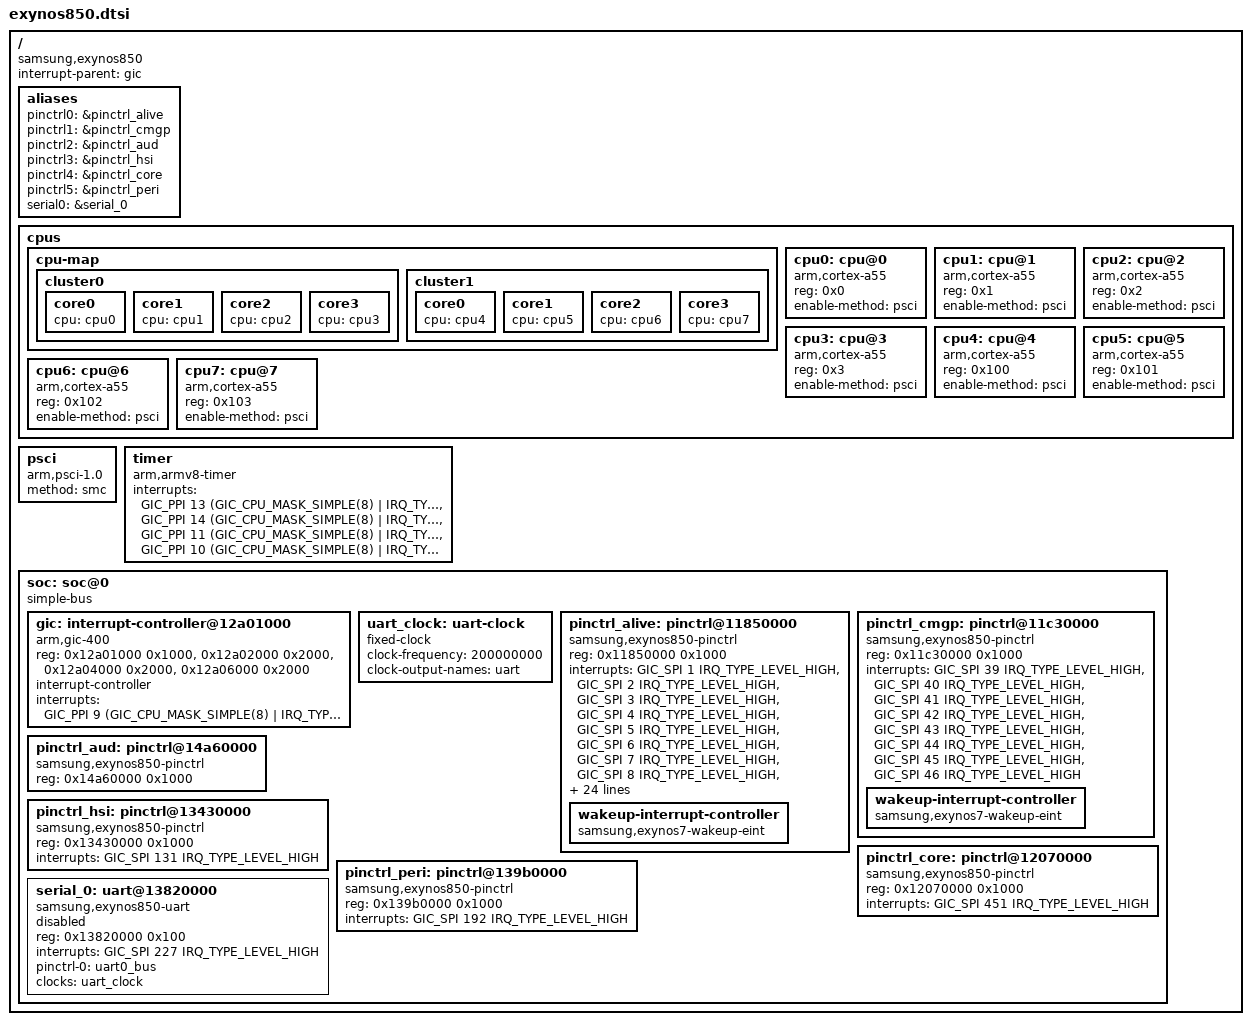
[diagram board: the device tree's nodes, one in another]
// SPDX-License-Identifier: GPL-2.0
/*
 * Samsung Exynos850 SoC device tree source
 *
 * Copyright (C) 2018 Samsung Electronics Co., Ltd.
 * Copyright (C) 2021 Linaro Ltd.
 *
 * Samsung Exynos850 SoC device nodes are listed in this file.
 * Exynos based board files can include this file and provide
 * values for board specific bindings.
 */

#include <dt-bindings/interrupt-controller/arm-gic.h>

/ {
	/* Also known under engineering name Exynos3830 */
	compatible = "samsung,exynos850";
	interrupt-parent = <&gic>;
	#address-cells = <2>;
	#size-cells = <1>;

	aliases {
		pinctrl0 = &pinctrl_alive;
		pinctrl1 = &pinctrl_cmgp;
		pinctrl2 = &pinctrl_aud;
		pinctrl3 = &pinctrl_hsi;
		pinctrl4 = &pinctrl_core;
		pinctrl5 = &pinctrl_peri;
		serial0 = &serial_0;
	};

	cpus {
		#address-cells = <1>;
		#size-cells = <0>;

		cpu-map {
			cluster0 {
				core0 {
					cpu = <&cpu0>;
				};
				core1 {
					cpu = <&cpu1>;
				};
				core2 {
					cpu = <&cpu2>;
				};
				core3 {
					cpu = <&cpu3>;
				};
			};

			cluster1 {
				core0 {
					cpu = <&cpu4>;
				};
				core1 {
					cpu = <&cpu5>;
				};
				core2 {
					cpu = <&cpu6>;
				};
				core3 {
					cpu = <&cpu7>;
				};
			};
		};

		cpu0: cpu@0 {
			device_type = "cpu";
			compatible = "arm,cortex-a55";
			reg = <0x0>;
			enable-method = "psci";
		};
		cpu1: cpu@1 {
			device_type = "cpu";
			compatible = "arm,cortex-a55";
			reg = <0x1>;
			enable-method = "psci";
		};
		cpu2: cpu@2 {
			device_type = "cpu";
			compatible = "arm,cortex-a55";
			reg = <0x2>;
			enable-method = "psci";
		};
		cpu3: cpu@3 {
			device_type = "cpu";
			compatible = "arm,cortex-a55";
			reg = <0x3>;
			enable-method = "psci";
		};
		cpu4: cpu@4 {
			device_type = "cpu";
			compatible = "arm,cortex-a55";
			reg = <0x100>;
			enable-method = "psci";
		};
		cpu5: cpu@5 {
			device_type = "cpu";
			compatible = "arm,cortex-a55";
			reg = <0x101>;
			enable-method = "psci";
		};
		cpu6: cpu@6 {
			device_type = "cpu";
			compatible = "arm,cortex-a55";
			reg = <0x102>;
			enable-method = "psci";
		};
		cpu7: cpu@7 {
			device_type = "cpu";
			compatible = "arm,cortex-a55";
			reg = <0x103>;
			enable-method = "psci";
		};
	};

	psci {
		compatible = "arm,psci-1.0";
		method = "smc";
	};

	timer {
		compatible = "arm,armv8-timer";
		/* Hypervisor Virtual Timer interrupt is not wired to GIC */
		interrupts = <GIC_PPI 13 (GIC_CPU_MASK_SIMPLE(8) |
					  IRQ_TYPE_LEVEL_LOW)>,
			     <GIC_PPI 14 (GIC_CPU_MASK_SIMPLE(8) |
					  IRQ_TYPE_LEVEL_LOW)>,
			     <GIC_PPI 11 (GIC_CPU_MASK_SIMPLE(8) |
					  IRQ_TYPE_LEVEL_LOW)>,
			     <GIC_PPI 10 (GIC_CPU_MASK_SIMPLE(8) |
					  IRQ_TYPE_LEVEL_LOW)>;
	};

	soc: soc@0 {
		compatible = "simple-bus";
		#address-cells = <1>;
		#size-cells = <1>;
		ranges = <0x0 0x0 0x0 0x20000000>;

		gic: interrupt-controller@12a01000 {
			compatible = "arm,gic-400";
			#interrupt-cells = <3>;
			#address-cells = <0>;
			reg = <0x12a01000 0x1000>,
			      <0x12a02000 0x2000>,
			      <0x12a04000 0x2000>,
			      <0x12a06000 0x2000>;
			interrupt-controller;
			interrupts = <GIC_PPI 9 (GIC_CPU_MASK_SIMPLE(8) |
						 IRQ_TYPE_LEVEL_HIGH)>;
		};

		/*
		 * Keep the stub clock for serial driver, until proper clock
		 * driver is implemented.
		 */
		uart_clock: uart-clock {
			compatible = "fixed-clock";
			#clock-cells = <0>;
			clock-frequency = <200000000>;
			clock-output-names = "uart";
		};

		pinctrl_alive: pinctrl@11850000 {
			compatible = "samsung,exynos850-pinctrl";
			reg = <0x11850000 0x1000>;
			interrupts = <GIC_SPI 1 IRQ_TYPE_LEVEL_HIGH>,
				     <GIC_SPI 2 IRQ_TYPE_LEVEL_HIGH>,
				     <GIC_SPI 3 IRQ_TYPE_LEVEL_HIGH>,
				     <GIC_SPI 4 IRQ_TYPE_LEVEL_HIGH>,
				     <GIC_SPI 5 IRQ_TYPE_LEVEL_HIGH>,
				     <GIC_SPI 6 IRQ_TYPE_LEVEL_HIGH>,
				     <GIC_SPI 7 IRQ_TYPE_LEVEL_HIGH>,
				     <GIC_SPI 8 IRQ_TYPE_LEVEL_HIGH>,
				     <GIC_SPI 9 IRQ_TYPE_LEVEL_HIGH>,
				     <GIC_SPI 10 IRQ_TYPE_LEVEL_HIGH>,
				     <GIC_SPI 11 IRQ_TYPE_LEVEL_HIGH>,
				     <GIC_SPI 12 IRQ_TYPE_LEVEL_HIGH>,
				     <GIC_SPI 13 IRQ_TYPE_LEVEL_HIGH>,
				     <GIC_SPI 14 IRQ_TYPE_LEVEL_HIGH>,
				     <GIC_SPI 15 IRQ_TYPE_LEVEL_HIGH>,
				     <GIC_SPI 16 IRQ_TYPE_LEVEL_HIGH>,
				     <GIC_SPI 17 IRQ_TYPE_LEVEL_HIGH>,
				     <GIC_SPI 18 IRQ_TYPE_LEVEL_HIGH>,
				     <GIC_SPI 19 IRQ_TYPE_LEVEL_HIGH>,
				     <GIC_SPI 20 IRQ_TYPE_LEVEL_HIGH>,
				     <GIC_SPI 21 IRQ_TYPE_LEVEL_HIGH>,
				     <GIC_SPI 22 IRQ_TYPE_LEVEL_HIGH>,
				     <GIC_SPI 23 IRQ_TYPE_LEVEL_HIGH>,
				     <GIC_SPI 24 IRQ_TYPE_LEVEL_HIGH>,
				     <GIC_SPI 25 IRQ_TYPE_LEVEL_HIGH>,
				     <GIC_SPI 26 IRQ_TYPE_LEVEL_HIGH>,
				     <GIC_SPI 27 IRQ_TYPE_LEVEL_HIGH>,
				     <GIC_SPI 28 IRQ_TYPE_LEVEL_HIGH>,
				     <GIC_SPI 29 IRQ_TYPE_LEVEL_HIGH>,
				     <GIC_SPI 30 IRQ_TYPE_LEVEL_HIGH>,
				     <GIC_SPI 31 IRQ_TYPE_LEVEL_HIGH>,
				     <GIC_SPI 32 IRQ_TYPE_LEVEL_HIGH>;

			wakeup-interrupt-controller {
				compatible = "samsung,exynos7-wakeup-eint";
			};
		};

		pinctrl_cmgp: pinctrl@11c30000 {
			compatible = "samsung,exynos850-pinctrl";
			reg = <0x11c30000 0x1000>;
			interrupts = <GIC_SPI 39 IRQ_TYPE_LEVEL_HIGH>,
				     <GIC_SPI 40 IRQ_TYPE_LEVEL_HIGH>,
				     <GIC_SPI 41 IRQ_TYPE_LEVEL_HIGH>,
				     <GIC_SPI 42 IRQ_TYPE_LEVEL_HIGH>,
				     <GIC_SPI 43 IRQ_TYPE_LEVEL_HIGH>,
				     <GIC_SPI 44 IRQ_TYPE_LEVEL_HIGH>,
				     <GIC_SPI 45 IRQ_TYPE_LEVEL_HIGH>,
				     <GIC_SPI 46 IRQ_TYPE_LEVEL_HIGH>;

			wakeup-interrupt-controller {
				compatible = "samsung,exynos7-wakeup-eint";
			};
		};

		pinctrl_aud: pinctrl@14a60000 {
			compatible = "samsung,exynos850-pinctrl";
			reg = <0x14a60000 0x1000>;
		};

		pinctrl_hsi: pinctrl@13430000 {
			compatible = "samsung,exynos850-pinctrl";
			reg = <0x13430000 0x1000>;
			interrupts = <GIC_SPI 131 IRQ_TYPE_LEVEL_HIGH>;
		};

		pinctrl_core: pinctrl@12070000 {
			compatible = "samsung,exynos850-pinctrl";
			reg = <0x12070000 0x1000>;
			interrupts = <GIC_SPI 451 IRQ_TYPE_LEVEL_HIGH>;
		};

		pinctrl_peri: pinctrl@139b0000 {
			compatible = "samsung,exynos850-pinctrl";
			reg = <0x139b0000 0x1000>;
			interrupts = <GIC_SPI 192 IRQ_TYPE_LEVEL_HIGH>;
		};

		/* USI: UART */
		serial_0: uart@13820000 {
			compatible = "samsung,exynos850-uart";
			reg = <0x13820000 0x100>;
			interrupts = <GIC_SPI 227 IRQ_TYPE_LEVEL_HIGH>;
			pinctrl-names = "default";
			pinctrl-0 = <&uart0_bus>;
			clocks = <&uart_clock>;
			clock-names = "uart";
			status = "disabled";
		};
	};
};

#include "exynos850-pinctrl.dtsi"
